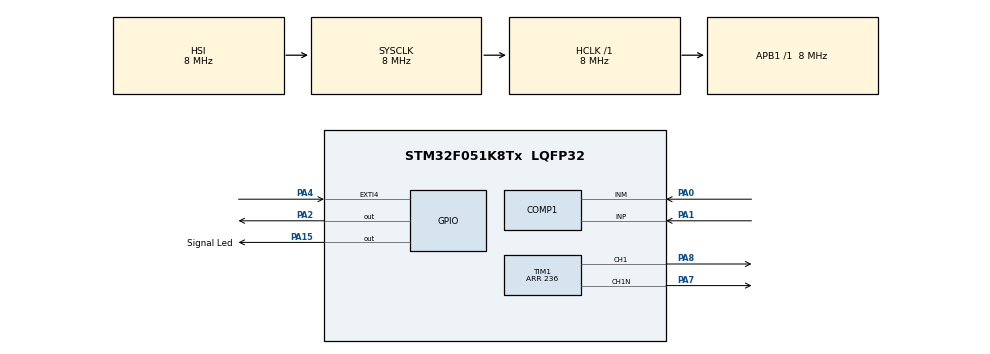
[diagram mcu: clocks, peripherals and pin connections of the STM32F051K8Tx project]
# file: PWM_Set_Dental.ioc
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COMP1.TriggerMode=COMP_TRIGGERMODE_IT_RISING_FALLING
FREERTOS.Tasks01=defaultTask,0,128,StartDefaultTask,Default,NULL
Mcu.Family=STM32F0
Mcu.Name=STM32F051K8Tx
Mcu.Package=LQFP32
NVIC.ADC1_COMP_IRQn=true\:3\:0\:false\:false\:true\:true\:false
NVIC.EXTI4_15_IRQn=true\:3\:0\:false\:true\:true\:1\:true\:true
NVIC.TIM2_IRQn=true\:0\:0\:false\:false\:true\:false\:false
NVIC.TimeBase=TIM2_IRQn
NVIC.TimeBaseIP=TIM2
PA0.Mode=INM
PA0.Signal=COMP1_INM
PA1.Mode=INP
PA1.Signal=COMP1_INP
PA13.Mode=Serial_Wire
PA13.Signal=SYS_SWDIO
PA14.Mode=Serial_Wire
PA14.Signal=SYS_SWCLK
PA15.GPIO_Label=Signal Led
PA15.Signal=GPIO_Output
PA2.Signal=GPIO_Output
PA4.GPIO_ModeDefaultEXTI=GPIO_MODE_IT_RISING_FALLING
PA4.Signal=GPXTI4
PA7.Mode=PWM Generation1 CH1 CH1N
PA7.Signal=TIM1_CH1N
PA8.Signal=S_TIM1_CH1
ProjectManager.HeapSize=0x200
ProjectManager.StackSize=0x400
ProjectManager.TargetToolchain=MDK-ARM V5
RCC.AHBFreq_Value=8000000
RCC.APB1Freq_Value=8000000
RCC.APB1TimFreq_Value=8000000
RCC.HCLKFreq_Value=8000000
RCC.PLLMUL=RCC_PLL_MUL12
RCC.SYSCLKFreq_VALUE=8000000
SH.S_TIM1_CH1.0=TIM1_CH1,PWM Generation1 CH1 CH1N
TIM1.Channel-PWM\ Generation1\ CH1\ CH1N=TIM_CHANNEL_1
TIM1.DeadTime=10
TIM1.Period=236
TIM1.Pulse-PWM\ Generation1\ CH1\ CH1N=117
TIM1.TIM_MasterSlaveMode=TIM_MASTERSLAVEMODE_DISABLE
VP_FREERTOS_VS_ENABLE.Mode=Enabled
VP_SYS_VS_tim2.Mode=TIM2
board=PWM_Set_Dental

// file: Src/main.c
/**
  ******************************************************************************
  * @file           : main.c
  * @brief          : Main program body
  ******************************************************************************
  * This notice applies to any and all portions of this file
  * that are not between comment pairs USER CODE BEGIN and
  * USER CODE END. Other portions of this file, whether
  * inserted by the user or by software development tools
  * are owned by their respective copyright owners.
  *
  * Copyright (c) 2018 STMicroelectronics International N.V.
  * All rights reserved.
  *
  * Redistribution and use in source and binary forms, with or without
  * modification, are permitted, provided that the following conditions are met:
  *
  * 1. Redistribution of source code must retain the above copyright notice,
  *    this list of conditions and the following disclaimer.
  * 2. Redistributions in binary form must reproduce the above copyright notice,
  *    this list of conditions and the following disclaimer in the documentation
  *    and/or other materials provided with the distribution.
  * 3. Neither the name of STMicroelectronics nor the names of other
  *    contributors to this software may be used to endorse or promote products
  *    derived from this software without specific written permission.
  * 4. This software, including modifications and/or derivative works of this
  *    software, must execute solely and exclusively on microcontroller or
  *    microprocessor devices manufactured by or for STMicroelectronics.
  * 5. Redistribution and use of this software other than as permitted under
  *    this license is void and will automatically terminate your rights under
  *    this license.
  *
  * THIS SOFTWARE IS PROVIDED BY STMICROELECTRONICS AND CONTRIBUTORS "AS IS"
  * AND ANY EXPRESS, IMPLIED OR STATUTORY WARRANTIES, INCLUDING, BUT NOT
  * LIMITED TO, THE IMPLIED WARRANTIES OF MERCHANTABILITY, FITNESS FOR A
  * PARTICULAR PURPOSE AND NON-INFRINGEMENT OF THIRD PARTY INTELLECTUAL PROPERTY
  * RIGHTS ARE DISCLAIMED TO THE FULLEST EXTENT PERMITTED BY LAW. IN NO EVENT
  * SHALL STMICROELECTRONICS OR CONTRIBUTORS BE LIABLE FOR ANY DIRECT, INDIRECT,
  * INCIDENTAL, SPECIAL, EXEMPLARY, OR CONSEQUENTIAL DAMAGES (INCLUDING, BUT NOT
  * LIMITED TO, PROCUREMENT OF SUBSTITUTE GOODS OR SERVICES; LOSS OF USE, DATA,
  * OR PROFITS; OR BUSINESS INTERRUPTION) HOWEVER CAUSED AND ON ANY THEORY OF
  * LIABILITY, WHETHER IN CONTRACT, STRICT LIABILITY, OR TORT (INCLUDING
  * NEGLIGENCE OR OTHERWISE) ARISING IN ANY WAY OUT OF THE USE OF THIS SOFTWARE,
  * EVEN IF ADVISED OF THE POSSIBILITY OF SUCH DAMAGE.
  *
  ******************************************************************************
  */
#include "main.h"
#include "stm32f0xx_hal.h"
#include "cmsis_os.h"
#include "comp.h"
#include "tim.h"
#include "gpio.h"

/* USER CODE BEGIN PV */
/* Private variables ---------------------------------------------------------*/

/* USER CODE END PV */

void SystemClock_Config(void);
void MX_FREERTOS_Init(void);
static void MX_NVIC_Init(void);

/* USER CODE BEGIN PFP */
/* Private function prototypes -----------------------------------------------*/

/* USER CODE END PFP */

int main(void)
{

  /* MCU Configuration----------------------------------------------------------*/

  /* Reset of all peripherals, Initializes the Flash interface and the Systick. */
  HAL_Init();

  /* Configure the system clock */
  SystemClock_Config();

  /* Initialize all configured peripherals */
  MX_GPIO_Init();
  MX_TIM1_Init();
  MX_COMP1_Init();

  /* Initialize interrupts */
  MX_NVIC_Init();
  /* USER CODE BEGIN 2 */
	//Vozmogno nygno ybrat' zapysk shima.
	HAL_GPIO_WritePin(GPIOA, GPIO_PIN_2, GPIO_PIN_SET);
	HAL_TIM_PWM_Start(&htim1, TIM_CHANNEL_1);
	HAL_TIMEx_PWMN_Start(&htim1, TIM_CHANNEL_1);
	HAL_COMP_Start_IT(&hcomp1);
  /* USER CODE END 2 */

  /* Call init function for freertos objects (in freertos.c) */
  MX_FREERTOS_Init();

  /* Start scheduler */
  osKernelStart();

  /* We should never get here as control is now taken by the scheduler */

  /* Infinite loop */
  while (1)
  {

  }

}

void SystemClock_Config(void)
{

  RCC_OscInitTypeDef RCC_OscInitStruct;
  RCC_ClkInitTypeDef RCC_ClkInitStruct;

    /**Initializes the CPU, AHB and APB busses clocks
    */
  RCC_OscInitStruct.OscillatorType = RCC_OSCILLATORTYPE_HSI;
  RCC_OscInitStruct.HSIState = RCC_HSI_ON;
  RCC_OscInitStruct.HSICalibrationValue = 16;
  RCC_OscInitStruct.PLL.PLLState = RCC_PLL_NONE;
  if (HAL_RCC_OscConfig(&RCC_OscInitStruct) != HAL_OK)
  {
    _Error_Handler(__FILE__, __LINE__);
  }

    /**Initializes the CPU, AHB and APB busses clocks
    */
  RCC_ClkInitStruct.ClockType = RCC_CLOCKTYPE_HCLK|RCC_CLOCKTYPE_SYSCLK
                              |RCC_CLOCKTYPE_PCLK1;
  RCC_ClkInitStruct.SYSCLKSource = RCC_SYSCLKSOURCE_HSI;
  RCC_ClkInitStruct.AHBCLKDivider = RCC_SYSCLK_DIV1;
  RCC_ClkInitStruct.APB1CLKDivider = RCC_HCLK_DIV1;

  if (HAL_RCC_ClockConfig(&RCC_ClkInitStruct, FLASH_LATENCY_0) != HAL_OK)
  {
    _Error_Handler(__FILE__, __LINE__);
  }

    /**Configure the Systick interrupt time
    */
  HAL_SYSTICK_Config(HAL_RCC_GetHCLKFreq()/1000);

    /**Configure the Systick
    */
  HAL_SYSTICK_CLKSourceConfig(SYSTICK_CLKSOURCE_HCLK);

  /* SysTick_IRQn interrupt configuration */
  HAL_NVIC_SetPriority(SysTick_IRQn, 3, 0);
}

/**
  * @brief NVIC Configuration.
  * @retval None
  */
static void MX_NVIC_Init(void)
{
  /* EXTI4_15_IRQn interrupt configuration */
  HAL_NVIC_SetPriority(EXTI4_15_IRQn, 3, 0);
  HAL_NVIC_EnableIRQ(EXTI4_15_IRQn);
}

void HAL_TIM_PeriodElapsedCallback(TIM_HandleTypeDef *htim)
{
  if (htim->Instance == TIM2) {
    HAL_IncTick();
  }
}

void _Error_Handler(char *file, int line)
{
  while(1)
  {
  }
}

/************************ (C) COPYRIGHT STMicroelectronics *****END OF FILE****/
